# YTM32Z1LS0 register map
Vendor: YTMicro; File version: 1.2
CPU: CM0PLUS r0p1, little endian, MPU, FPU, 2 interrupt priority bits
Registers are 32-bit, read-write, reset 0x0 unless marked. A register's access mark holds for its fields unless they carry their own. Offsets are from the block's base; [hi:lo] are bit positions; {n}, {i} and the like mark numbered series; 'fields as' and 'values as' point back to an identical list.

## UART0 — UART module with LIN mode support
Base 0x4006A000; register names take the prefix UART0_
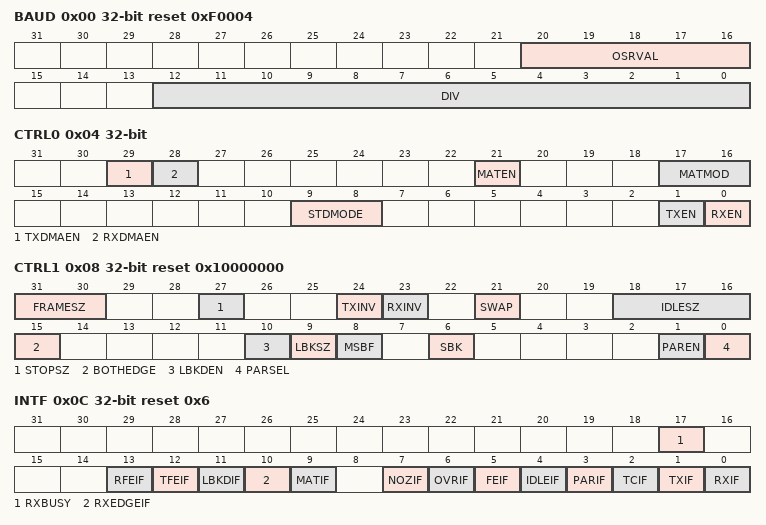
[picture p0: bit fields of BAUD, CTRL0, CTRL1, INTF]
0x00 BAUD reset 0xF0004
  [20:16] OSRVAL — Over sample config, only support update when module disabled
    0=Over sample value is 16; {v}=Over sample value is {v+1}, need to set BOTHEDGE bit (v=3..6); {v}=Over sample value is {v+1} (v=7..31)
  [12:0] DIV — Function clock divider to generate sample baudrate clock
    1=Divider value is 1; 2=Divider value is 2
0x04 CTRL0
  [29] TXDMAEN — TX DATA request DMA enable when TX fifo less than watermark or buff empty
    0=DMA request disabled; 1=DMA request enabled
  [28] RXDMAEN — RX DATA request DMA enable when RX fifo great than watermark or buff full
    0=DMA request disabled; 1=DMA request enabled
  [21] MATEN — Setting this bit will enable RX data match logic in UART
    0=UART data match disable; 1=UART data match enable
  [17:16] MATMOD
    0=Address match wakeup; 1=Idle match wakeup; 2=Match on and match off
  [9:8] STDMODE
    0=Normal working mode; 1=standby working mode with idle line wakeup; 3=standby working mode with address match wakeup
  [1] TXEN
    0=TX logic is disabled; 1=TX logic is enabled
  [0] RXEN
    0=RX logic is disabled; 1=RX logic is enabled
0x08 CTRL1 reset 0x10000000
  [31:30] FRAMESZ — Control bit count in one frame transfer
    {v}={v+7}-bit data mode (v=0..3)
  [27] STOPSZ — Stop bit size selection
    0=1-bit stop; 1=2-bit stop
  [24] TXINV — Invert TX line output, this bit will change data, start, stop, break and idle polarity.
    0=TX data line is not inverted; 1=TX data line is inverted
  [23] RXINV — Invert RX line input, this bit will change data, start, stop, break and idle polarity.
    0=RX data line is not inverted; 1=RX data line is inverted
  [21] SWAP — Swap TX and RX lines
    0=TX RX line under normal mode; 1=Swap TX and RX lines, data input on TX, data output to RX
  [18:16] IDLESZ — IDLE detection bytes size
    0=1 idle character; 1=2 idle character; 2=4 idle character; 3=8 idle character; 4=16 idle character; 5=32 idle character; 6=64 idle character; 7=128 idle character
  [15] BOTHEDGE — Setting this bit allows uart sample data on both rising and falling of baudrate clock. This bit need to set when BAUD[OSRVAL] less than 7, only support update when RX logic disabled.
  [10] LBKDEN — LBKDEN enable UART detection LIN break, and the break character is not stored in RX FIFO
    0=LIN break detection is disabled; 1=LIN break detection is enabled
  [9] LBKSZ
    0=Break character is transmitted with length of 9 to 13 bit times; 1=Break character is transmitted with length of 12 to 15 bit times
  [8] MSBF — Setting this bit will change following data transfer shift order
    0=LSB is shifted out first after start bit; 1=MSB is shifted out first after start bit
  [6] SBK — Send LIN break out, when SBK bit set, UART will send out LIN break continuously until SBK bit cleared.
    0=Normal mode; 1=Send out continuous LIN break
  [1] PAREN — Setting this bit will enable UART hardware parity check/generation on both RX and TX
    0=Hardware parity feature disabled; 1=Hardware parity feature enabled on RX and TX
  [0] PARSEL — Valid when PAREN bit set, PARSEL control UART use odd or even parity check/generation
    0=Even parity; 1=Odd parity
0x0C INTF reset 0x6
  [17] RXBUSY ro
    0=RX line idle and wait for data; 1=RX is receiving data
  [13] RFEIF — RX FIFO underflow happened, read RX FIFO when RX FIFO empty will set this bit
    0=No RX FIFO underflow detected; 1=RX FIFO underflow detected
  [12] TFEIF — TX FIFO overflow happened, write TX FIFO when RX FIFO full will set this bit
    0=No TX FIFO overflow detected; 1=TX FIFO overflow detected
  [11] LBKDIF
    0=LIN break not detected; 1=LIN break detected
  [10] RXEDGEIF
    0=UART RX active edge not detected; 1=UART RX active edge detected
  [9] MATIF
    0=UART RX data match not detected; 1=UART RX data match detected
  [7] NOZIF
    0=UART RX noise not detected; 1=UART RX noise detected
  [6] OVRIF — UART received new data when RX FIFO is full will set this bit ewline ote{User have to clear this bit before receiving new data after RX FIFO not full.}
    0=UART RX overrun not detected; 1=UART RX overrun detected, and no new data will be stored
  [5] FEIF — FEIF set when no valid STOP bit received after data phase
    0=UART RX frame error not detected; 1=UART RX frame error detected
  [4] IDLEIF — IDLE set when UART RX line keeps high time longer than idle condition setting. after bit cleared, idle flag won't set unless new data received.
    0=UART RX idle not detected; 1=UART RX idle detected
  [3] PARIF — Parity check error happened when hardware calculated parity bit not match received.
    0=UART RX data parity error not detected; 1=UART RX data parity error detected
  [2] TCIF ro — TCIF cleared when write TX data and TX start send data, TCIF set when TX line idle
    0=UART transmitter is busy and transmitting data; 1=UART transmitter is idle
  [1] TXIF ro — Indicates words in TX FIFO is equal or less than TX FIFO watermark setting
    0=Word in TX FIFO is greater than watermark; 1=Word in TX FIFO is equal or less than watermark, request to write new data
  [0] RXIF ro — Indicates words in RX FIFO is greater than RX FIFO watermark setting
    0=Word in RX FIFO is equal or less than watermark; 1=Word in RX FIFO is greater than watermark, should read data register
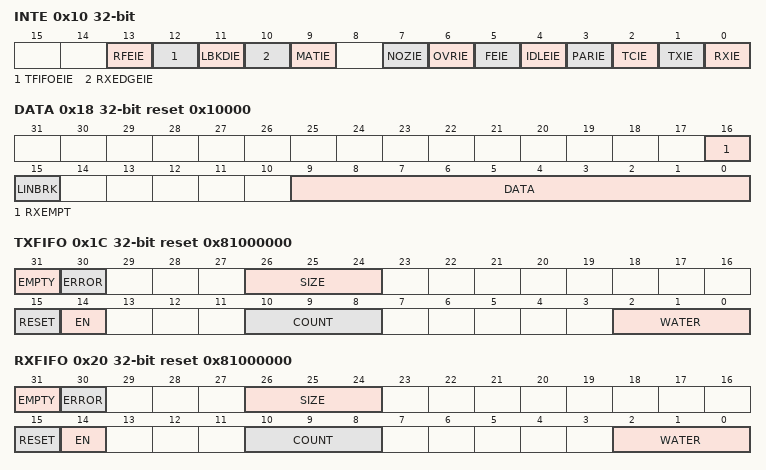
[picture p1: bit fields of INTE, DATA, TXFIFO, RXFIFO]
0x10 INTE
  [all] fields
    0=Interrupt disabled; 1=Interrupt enabled
  [13] RFEIE
  [12] TFIFOEIE
  [11] LBKDIE
  [10] RXEDGEIE
  [9] MATIE
  [7] NOZIE
  [6] OVRIE
  [5] FEIE
  [4] IDLEIE
  [3] PARIE
  [2] TCIE
  [1] TXIE
  [0] RXIE
0x14 MATCH
  [9:0] DATA — Data match compare value
0x18 DATA reset 0x10000 — Reading DATA register will return received data in RX FIFO, writing DATA register will push data to TX FIFO and waiting for transfer. ote{This register only support 32-bit access.}
  [16] RXEMPT ro
    0=UART RX FIFO is not empty, reading data is valid; 1=UART RX FIFO is empty, reading data is invalid
  [15] LINBRK wo — Writing LINBRK bit will let UART send out LIN break instead of DATA
  [9:0] DATA — Reading DATA field will return data in RX FIFO, writing DATA field will push data to TX FIFO
0x1C TXFIFO reset 0x81000000
  [31] EMPTY ro — TX FIFO empty, asserts when there is no data in the TX FIFO.
    1=TX FIFO is empty
  [30] ERROR ro — Writing TX FIFO with TX FIFO full will set ERROR bit
    1=TX FIFO has overflow error
  [26:24] SIZE ro — Available TX FIFO Size is 2^SIZE words
  [15] RESET wo — Reset TX FIFO address pointer
  [14] EN
    0=FIFO is not enabled, data buffer is used; 1=FIFO is enabled
  [10:8] COUNT ro — TX FIFO current data count
  [2:0] WATER — TXIF set when words count in TX FIFO equal or less than watermark
0x20 RXFIFO reset 0x81000000
  [31] EMPTY ro — RX FIFO empty, asserts when there is no data in the RX FIFO.
  [30] ERROR ro — Reading RX FIFO with RX FIFO empty will set ERROR bit
    1=RX FIFO has underflow error
  [26:24] SIZE ro — Available RX FIFO Size is 2^SIZE words
  [15] RESET wo — Reset RX FIFO address pointer
  [14] EN
    values as TXFIFO.EN
  [10:8] COUNT — RX FIFO current data count
  [2:0] WATER — RXIF set when words count in RX FIFO greater than watermark

## UART1 — UART module with LIN mode support
Base 0x4006B000; register names take the prefix UART1_
Registers as UART0.

## UART2 — UART module with LIN mode support
Base 0x4006C000; register names take the prefix UART2_
Registers as UART0.
